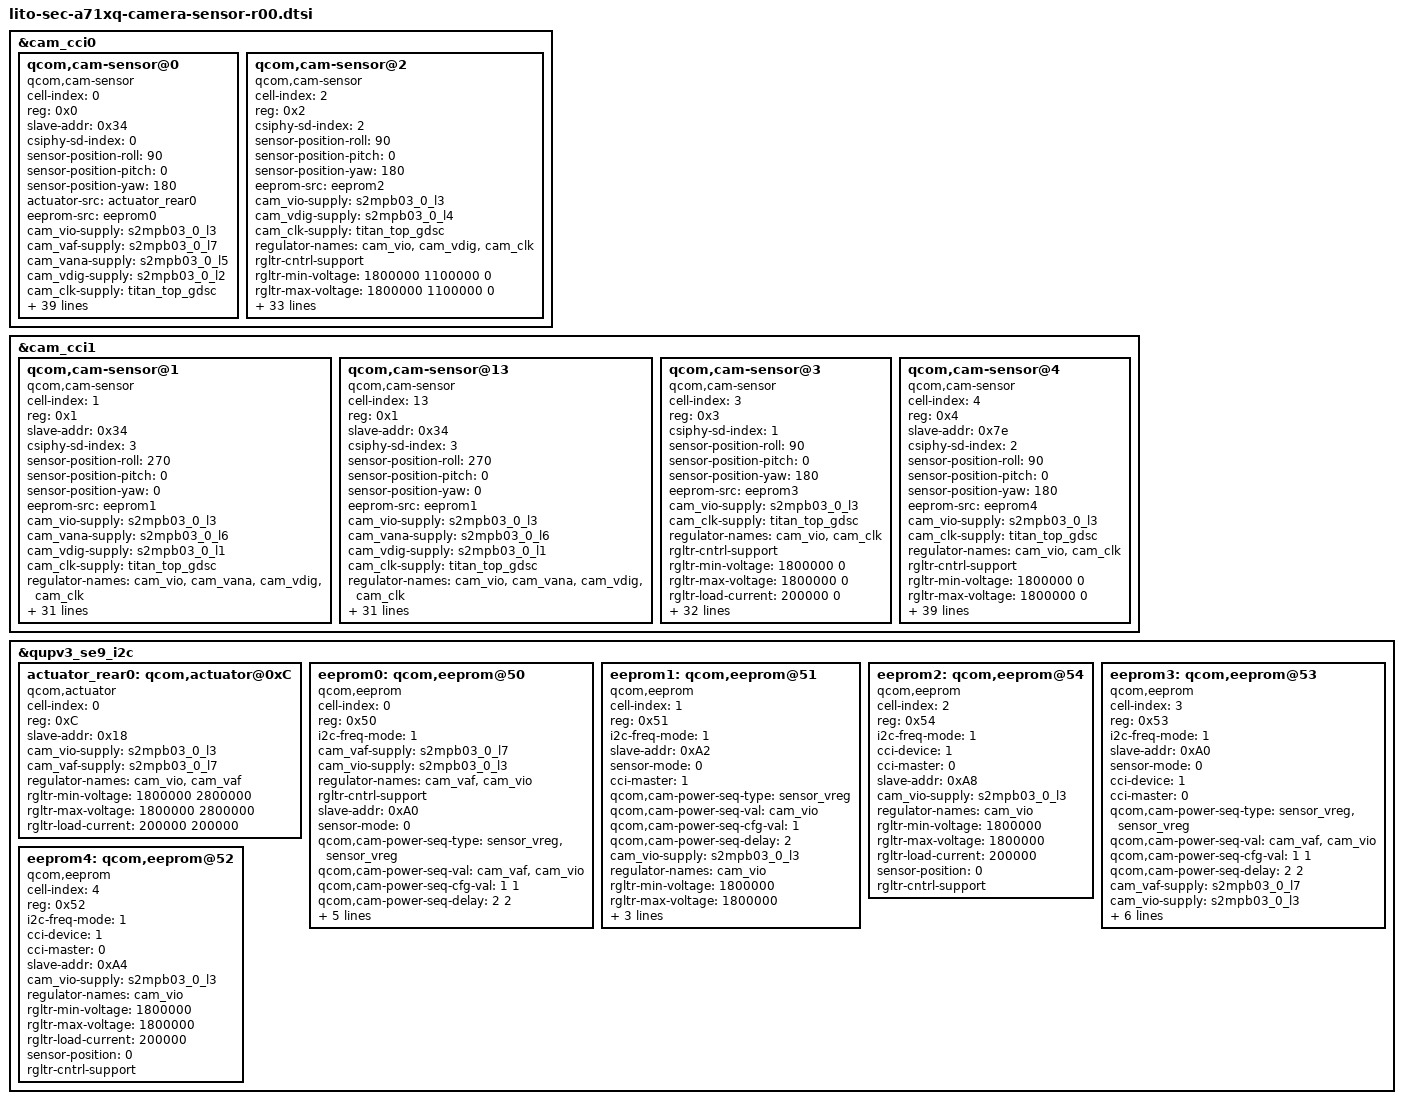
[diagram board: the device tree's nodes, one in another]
/*
 * Copyright (c) 2019, The Linux Foundation. All rights reserved.
 *
 * This program is free software; you can redistribute it and/or modify
 * it under the terms of the GNU General Public License version 2 and
 * only version 2 as published by the Free Software Foundation.
 *
 * This program is distributed in the hope that it will be useful,
 * but WITHOUT ANY WARRANTY; without even the implied warranty of
 * MERCHANTABILITY or FITNESS FOR A PARTICULAR PURPOSE.  See the
 * GNU General Public License for more details.
 */
#include <dt-bindings/clock/qcom,camcc-lito.h>

&cam_cci0 {
	qcom,cam-sensor@0 {
		cell-index = <0>;
		compatible = "qcom,cam-sensor";
		reg = <0x0>;
                slave-addr = <0x34>;
		csiphy-sd-index = <0>;
		sensor-position-roll = <90>;
		sensor-position-pitch = <0>;
		sensor-position-yaw = <180>;

		actuator-src = <&actuator_rear0>;
		//led-flash-src = <&led_flash0>;
		eeprom-src = <&eeprom0>;

		// LDO
		cam_vio-supply = <&s2mpb03_0_l3>;
		cam_vaf-supply = <&s2mpb03_0_l7>;
		cam_vana-supply = <&s2mpb03_0_l5>;
		cam_vdig-supply = <&s2mpb03_0_l2>;
		cam_clk-supply = <&titan_top_gdsc>;
		regulator-names = "cam_vio","cam_vaf", "cam_vana", "cam_vdig", "cam_clk";
		rgltr-cntrl-support;
		rgltr-min-voltage = <1800000 2800000 2900000 1100000 0>;
		rgltr-max-voltage = <1800000 2800000 2900000 1100000 0>;
		rgltr-load-current = <200000 200000 200000 200000 0>;

		// GPIO
		gpio-no-mux = <0>;
		pinctrl-names = "cam_default", "cam_suspend";
		pinctrl-0 = <&cam_sensor_mclk0_active &cam_sensor_rear_active &rcam0_avdd_1p8_active>;
		pinctrl-1 = <&cam_sensor_mclk0_suspend &cam_sensor_rear_suspend &rcam0_avdd_1p8_suspend>;

		gpios = <&tlmm 13 0>,  // MCLK 
			<&tlmm 30 0>,     // RST 
			<&tlmm 22 0>;
		gpio-reset = <1>;
		gpio-req-tbl-num = <0 1 2>;
		gpio-req-tbl-flags = <1 0 0>;
		gpio-req-tbl-label = "CAMIF_MCLK0", "CAM_RESET0", "RCAM0_AV1P8";


		sensor-mode = <0>;
		cci-device = <0>;
		cci-master = <0>;
		status = "ok";
		clocks = <&camcc CAM_CC_MCLK0_CLK>;
		clock-names = "cam_clk";
		clock-cntl-level = "turbo";
		clock-rates = <19200000>;

		cam,isp = <0>;                  // 0 : INT , 1 : EXT , 2 : SOC
		cam,cal_memory = <2>;           // 0 : N , 1 : FROM , 2 : EEPROM , 3 : OTP
		cam,read_version = <1>;         // 0 : SYSFS , 1 : CAMON
		cam,core_voltage = <1>;         // 0 : N , 1 : Y
		cam,upgrade = <2>;              // 0 : N , 1 : SYSFS , 2 : CAMON
		cam,fw_write = <3>;             // 0 : N , 1 : OS , 2 : SD , 3 : ALL
		cam,fw_dump = <1>;              // 0 : N , 1 : Y
		cam,companion_chip = <0>;       // 0 : N , 1 : Y
		cam,ois = <0>;                  // 0 : N , 1 : Y
		cam,dual_open = <0>;            // 0 : N , 1 : Y
		cam,valid = <1>;                // 0 : N , 1 : Y
	};

	qcom,cam-sensor@2 { // REAR CAM 2 - 13MP UW 
		cell-index = <2>;
		compatible = "qcom,cam-sensor";
		reg = <0x2>;
		csiphy-sd-index = <2>;
		sensor-position-roll = <90>;
		sensor-position-pitch = <0>;
		sensor-position-yaw = <180>;
		eeprom-src = <&eeprom2>;
		
		cam_vio-supply = <&s2mpb03_0_l3>;
		cam_vdig-supply = <&s2mpb03_0_l4>; 
		cam_clk-supply = <&titan_top_gdsc>;
		regulator-names =  "cam_vio", "cam_vdig", "cam_clk";
		rgltr-cntrl-support;
		rgltr-min-voltage = <1800000 1100000 0>;
		rgltr-max-voltage = <1800000 1100000 0>;
		rgltr-load-current = <200000 200000 0>;

		gpio-no-mux = <0>;
		pinctrl-names = "cam_default", "cam_suspend";
		pinctrl-0 = <&cam_sensor_mclk3_active &cam_sensor_rear3sw_active &cam_rear3_pwr_active &cam_mipi_sel_active>;
		pinctrl-1 = <&cam_sensor_mclk3_suspend &cam_sensor_rear3sw_suspend &cam_rear3_pwr_suspend &cam_mipi_sel_suspend>;
		gpios = <&tlmm 15 0>, // MCLK 
		       	<&tlmm 21 0>, // RESET 
		        <&tlmm 4 0>, // VANA
		        <&tlmm 66 0>; //MIPI SEL	    



		gpio-reset = <1>;
		gpio-vana = <2>;
		gpio-custom1 = <3>;
		gpio-req-tbl-num = <0 1 2 3>;
		gpio-req-tbl-flags = <1 0 0 0>;
		gpio-req-tbl-label = "CAMIF_MCLK2", "CAM_RESET3", "CAM_VANA", "MIPI_SEL";
		
		sensor-mode = <0>;
		cci-device = <0>;
		cci-master = <1>;
		status = "ok";
		clocks = <&camcc CAM_CC_MCLK2_CLK>;
		clock-names = "cam_clk";
		clock-cntl-level = "turbo";
		clock-rates = <24000000>;

		cam,isp = <0>;                  // 0 : INT , 1 : EXT , 2 : SOC
		cam,cal_memory = <2>;           // 0 : N , 1 : FROM , 2 : EEPROM , 3 : OTP
		cam,read_version = <1>;         // 0 : SYSFS , 1 : CAMON
		cam,core_voltage = <1>;         // 0 : N , 1 : Y
		cam,upgrade = <2>;              // 0 : N , 1 : SYSFS , 2 : CAMON
		cam,fw_write = <3>;             // 0 : N , 1 : OS , 2 : SD , 3 : ALL
		cam,fw_dump = <1>;              // 0 : N , 1 : Y
		cam,companion_chip = <0>;       // 0 : N , 1 : Y
		cam,ois = <0>;                  // 0 : N , 1 : Y
		cam,dual_open = <0>;            // 0 : N , 1 : Y
		cam,valid = <1>;                // 0 : N , 1 : Y
	};
};

&cam_cci1 {
	qcom,cam-sensor@1 {   // VT 32M 
		cell-index = <1>;
		compatible = "qcom,cam-sensor";
		reg = <0x1>;
		slave-addr = <0x34>;
		csiphy-sd-index = <3>;
		sensor-position-roll = <270>;
		sensor-position-pitch = <0>;
		sensor-position-yaw = <0>;

		eeprom-src = <&eeprom1>;

		// LDO
		cam_vio-supply = <&s2mpb03_0_l3>;
		cam_vana-supply = <&s2mpb03_0_l6>;
		cam_vdig-supply = <&s2mpb03_0_l1>;
		cam_clk-supply = <&titan_top_gdsc>;
		regulator-names = "cam_vio", "cam_vana", "cam_vdig", "cam_clk";
		rgltr-cntrl-support;
		rgltr-min-voltage = <1800000 2900000 1050000 0>;
		rgltr-max-voltage = <1800000 2900000 1050000 0>;
		rgltr-load-current = <200000 200000 200000 0>;

		// GPIO
		gpio-no-mux = <0>;
		pinctrl-names = "cam_default", "cam_suspend";
		pinctrl-0 = <&cam_sensor_mclk1_active &cam_sensor_front_active>;
		pinctrl-1 = <&cam_sensor_mclk1_suspend &cam_sensor_front_suspend >;

		gpios = <&tlmm 16 0>,  // MCLK
		     <&tlmm 91 0>;   //RST
			
			
		gpio-reset = <1>;
		gpio-req-tbl-num = <0 1>;
		gpio-req-tbl-flags = <1 0>;
		gpio-req-tbl-label = "CAMIF_MCLK2", "CAM_RESET2";

		sensor-mode = <0>;
		cci-device = <1>;
		cci-master = <0>;
		status = "ok";
		clocks = <&camcc CAM_CC_MCLK3_CLK>;
		clock-names = "cam_clk";
		clock-cntl-level = "turbo";
		clock-rates = <24000000>;

		cam,isp = <0>;                  // 0 : INT , 1 : EXT , 2 : SOC
		cam,cal_memory = <2>;           // 0 : N , 1 : FROM , 2 : EEPROM , 3 : OTP
		cam,read_version = <0>;         // 0 : SYSFS , 1 : CAMON
		cam,core_voltage = <0>;         // 0 : N , 1 : Y
		cam,upgrade = <0>;              // 0 : N , 1 : SYSFS , 2 : CAMON
		cam,fw_write = <0>;             // 0 : N , 1 : OS , 2 : SD , 3 : ALL
		cam,fw_dump = <0>;              // 0 : N , 1 : Y
		cam,companion_chip = <0>;       // 0 : N , 1 : Y
		cam,ois = <0>;                  // 0 : N , 1 : Y
		cam,dual_open = <0>;            // 0 : N , 1 : Y
		cam,valid = <1>;
	};
 
       qcom,cam-sensor@13 {   // VT 32M 
		cell-index = <13>;
		compatible = "qcom,cam-sensor";
		reg = <0x1>;
		slave-addr = <0x34>;
		csiphy-sd-index = <3>;
		sensor-position-roll = <270>;
		sensor-position-pitch = <0>;
		sensor-position-yaw = <0>;

		eeprom-src = <&eeprom1>;

		// LDO
		cam_vio-supply = <&s2mpb03_0_l3>;
		cam_vana-supply = <&s2mpb03_0_l6>;
		cam_vdig-supply = <&s2mpb03_0_l1>;
		cam_clk-supply = <&titan_top_gdsc>;
		regulator-names = "cam_vio", "cam_vana", "cam_vdig", "cam_clk";
		rgltr-cntrl-support;
		rgltr-min-voltage = <1800000 2900000 1050000 0>;
		rgltr-max-voltage = <1800000 2900000 1050000 0>;
		rgltr-load-current = <200000 200000 200000 0>;

		// GPIO
		gpio-no-mux = <0>;
		pinctrl-names = "cam_default", "cam_suspend";
		pinctrl-0 = <&cam_sensor_mclk1_active &cam_sensor_front_active>;
		pinctrl-1 = <&cam_sensor_mclk1_suspend &cam_sensor_front_suspend >;

		gpios = <&tlmm 16 0>,  // MCLK
		     <&tlmm 91 0>;   //RST
			
			
		gpio-reset = <1>;
		gpio-req-tbl-num = <0 1>;
		gpio-req-tbl-flags = <1 0>;
		gpio-req-tbl-label = "CAMIF_MCLK2", "CAM_RESET2";

		sensor-mode = <0>;
		cci-device = <1>;
		cci-master = <0>;
		status = "ok";
		clocks = <&camcc CAM_CC_MCLK3_CLK>;
		clock-names = "cam_clk";
		clock-cntl-level = "turbo";
		clock-rates = <24000000>;

		cam,isp = <0>;                  // 0 : INT , 1 : EXT , 2 : SOC
		cam,cal_memory = <2>;           // 0 : N , 1 : FROM , 2 : EEPROM , 3 : OTP
		cam,read_version = <0>;         // 0 : SYSFS , 1 : CAMON
		cam,core_voltage = <0>;         // 0 : N , 1 : Y
		cam,upgrade = <0>;              // 0 : N , 1 : SYSFS , 2 : CAMON
		cam,fw_write = <0>;             // 0 : N , 1 : OS , 2 : SD , 3 : ALL
		cam,fw_dump = <0>;              // 0 : N , 1 : Y
		cam,companion_chip = <0>;       // 0 : N , 1 : Y
		cam,ois = <0>;                  // 0 : N , 1 : Y
		cam,dual_open = <0>;            // 0 : N , 1 : Y
		cam,valid = <1>;
	};

	qcom,cam-sensor@3 {  // REAR CAM 3 - 5M 
		cell-index = <3>;
		compatible = "qcom,cam-sensor";
		reg = <0x3>;
		csiphy-sd-index = <1>;
		sensor-position-roll = <90>;
		sensor-position-pitch = <0>;
		sensor-position-yaw = <180>;
		eeprom-src = <&eeprom3>;


		// LDO
		cam_vio-supply = <&s2mpb03_0_l3>;
		cam_clk-supply = <&titan_top_gdsc>;
		regulator-names = "cam_vio", "cam_clk";
		rgltr-cntrl-support;
		rgltr-min-voltage = <1800000 0>;
		rgltr-max-voltage = <1800000 0>;
		rgltr-load-current = <200000 0>;

		// GPIO
		gpio-no-mux = <0>;
		pinctrl-names = "cam_default", "cam_suspend";
		pinctrl-0 = <&cam_sensor_mclk2_active &cam_sensor_rear_sub2_active &rcam2_avdd_active &rcam2_dvdd_active>;
		pinctrl-1 = <&cam_sensor_mclk2_suspend &cam_sensor_rear_sub2_suspend &rcam2_avdd_suspend &rcam2_dvdd_suspend>;

		gpios = <&tlmm 14 0>,
			<&tlmm 29 0>,
			<&tlmm 24 0>,
			<&tlmm 44 0>;

		gpio-reset = <1>;
		gpio-vana = <2>;
		gpio-vdig = <3>;
		gpio-req-tbl-num = <0 1 2 3>;
		gpio-req-tbl-flags = <1 0 0 0>;
		gpio-req-tbl-label = "CAMIF_MCLK3", "CAM_RESET2", "CAM_VANA", "CAM_VDIG";

		sensor-mode = <0>;
		cci-device = <1>;
		cci-master = <0>;
		status = "ok";
		clocks = <&camcc CAM_CC_MCLK1_CLK>;
		clock-names = "cam_clk";
		clock-cntl-level = "turbo";
		clock-rates = <24000000>;

		cam,isp = <0>;                  // 0 : INT , 1 : EXT , 2 : SOC
		cam,cal_memory = <0>;           // 0 : N , 1 : FROM , 2 : EEPROM , 3 : OTP
		cam,read_version = <0>;         // 0 : SYSFS , 1 : CAMON
		cam,core_voltage = <0>;         // 0 : N , 1 : Y
		cam,upgrade = <0>;              // 0 : N , 1 : SYSFS , 2 : CAMON
		cam,fw_write = <0>;             // 0 : N , 1 : OS , 2 : SD , 3 : ALL
		cam,fw_dump = <0>;              // 0 : N , 1 : Y
		cam,companion_chip = <0>;       // 0 : N , 1 : Y
		cam,ois = <0>;                  // 0 : N , 1 : Y
		cam,dual_open = <0>;            // 0 : N , 1 : Y
		cam,valid = <1>;
	};

	qcom,cam-sensor@4 {   //REAR CAM 4 - 5M Macro  
		cell-index = <4>;
		compatible = "qcom,cam-sensor";
		reg = <0x4>;
                slave-addr = <0x7e>;
		csiphy-sd-index = <2>;
		sensor-position-roll = <90>;
		sensor-position-pitch = <0>;
		sensor-position-yaw = <180>;
  		//led-flash-src = <&led_flash0>;
		eeprom-src = <&eeprom4>;

		// LDO
                cam_vio-supply = <&s2mpb03_0_l3>;
		cam_clk-supply = <&titan_top_gdsc>;
		regulator-names = "cam_vio", "cam_clk";
		rgltr-cntrl-support;
		rgltr-min-voltage = <1800000 0>;
		rgltr-max-voltage = <1800000 0>;
		rgltr-load-current = <200000 0>;


		// GPIO
		gpio-no-mux = <0>;
		pinctrl-names = "cam_default", "cam_suspend";
		pinctrl-0 = <&cam_sensor_mclk4_active &cam_sensor_rear4sw_active &cam_sensor_rear4_pwr_active &cam_sensor_rear4_digital_active &cam_mipi_sel_active>;
		pinctrl-1 = <&cam_sensor_mclk4_suspend &cam_sensor_rear4sw_suspend &cam_sensor_rear4_pwr_suspend &cam_sensor_rear4_digital_suspend &cam_mipi_sel_suspend>;

		gpios = <&tlmm 25 0>,
			<&tlmm 23 0>,
			<&tlmm 63 0>,
			<&tlmm 64 0>,
			<&tlmm 66 0>;

		gpio-reset = <1>;
		gpio-vana = <2>;
		gpio-vdig = <3>;
		gpio-custom1 = <4>;
		gpio-req-tbl-num = <0 1 2 3 4>;
		gpio-req-tbl-flags = <1 0 0 0 0>;
		gpio-req-tbl-label = "CAMIF_MCLK3", "CAM_RESET2", "CAM_VANA", "CAM_VDIG", "MIPI_SEL";

		sensor-mode = <0>;
		cci-device = <1>;
		cci-master = <0>;
		status = "ok";
		clocks = <&camcc CAM_CC_MCLK4_CLK>;
		clock-names = "cam_clk";
		clock-cntl-level = "turbo";
		clock-rates = <24000000>;

		cam,isp = <0>;                  // 0 : INT , 1 : EXT , 2 : SOC
		cam,cal_memory = <0>;           // 0 : N , 1 : FROM , 2 : EEPROM , 3 : OTP
		cam,read_version = <0>;         // 0 : SYSFS , 1 : CAMON
		cam,core_voltage = <0>;         // 0 : N , 1 : Y
		cam,upgrade = <0>;              // 0 : N , 1 : SYSFS , 2 : CAMON
		cam,fw_write = <0>;             // 0 : N , 1 : OS , 2 : SD , 3 : ALL
		cam,fw_dump = <0>;              // 0 : N , 1 : Y
		cam,companion_chip = <0>;       // 0 : N , 1 : Y
		cam,ois = <0>;                  // 0 : N , 1 : Y
		cam,dual_open = <0>;            // 0 : N , 1 : Y
		cam,valid = <1>;                // 0 : N , 1 : Y
	};
};

&qupv3_se9_i2c {
    status = "ok";
    actuator_rear0: qcom,actuator@0xC {
		cell-index = <0>;
		reg = <0xC>;
		slave-addr = <0x18>;
		compatible = "qcom,actuator";
		cam_vio-supply = <&s2mpb03_0_l3>;
		cam_vaf-supply = <&s2mpb03_0_l7>;
		regulator-names = "cam_vio","cam_vaf";
        	rgltr-min-voltage = <1800000 2800000>;
        	rgltr-max-voltage = <1800000 2800000>;
		rgltr-load-current = <200000 200000>;
	};

	eeprom0: qcom,eeprom@50 {
		cell-index = <0>;
		reg = <0x50>;
		compatible = "qcom,eeprom";
		i2c-freq-mode = <1>;
		cam_vaf-supply = <&s2mpb03_0_l7>;
		cam_vio-supply = <&s2mpb03_0_l3>;
		regulator-names = "cam_vaf","cam_vio";
		rgltr-cntrl-support;
		slave-addr = <0xA0>;
		sensor-mode = <0>;
		//cci-device = <1>;
		//cci-master = <0>;

		qcom,cam-power-seq-type = "sensor_vreg", "sensor_vreg";
        qcom,cam-power-seq-val = "cam_vaf", "cam_vio";
        qcom,cam-power-seq-cfg-val = <1 1>;
        qcom,cam-power-seq-delay = <2 2>;

		rgltr-min-voltage = <2800000 1800000>;
		rgltr-max-voltage = <2800000 1800000>;
		rgltr-load-current = <200000 200000>;
		sensor-position = <0>;

		gpio-no-mux = <0>;
	};

	eeprom1: qcom,eeprom@51 {
        cell-index = <1>;
        reg = <0x51>;//QUP use 0xA2, 51
        compatible = "qcom,eeprom";
        i2c-freq-mode = <1>;
        slave-addr = <0xA2>;
        sensor-mode = <0>;
        cci-master = <1>;

        qcom,cam-power-seq-type = "sensor_vreg";
        qcom,cam-power-seq-val = "cam_vio";
        qcom,cam-power-seq-cfg-val = <1>;
        qcom,cam-power-seq-delay = <2>;

        cam_vio-supply = <&s2mpb03_0_l3>;
        regulator-names = "cam_vio";
        rgltr-min-voltage = <1800000>;
        rgltr-max-voltage = <1800000>;
        rgltr-load-current = <200000>;

        sensor-position = <1>;
        rgltr-cntrl-support;
	};

    eeprom2: qcom,eeprom@54 {
        cell-index = <2>;
        reg = <0x54>;
        compatible = "qcom,eeprom";
        i2c-freq-mode = <1>;
        cci-device = <1>;
        cci-master = <0>;
        slave-addr = <0xA8>;

        cam_vio-supply = <&s2mpb03_0_l3>;

        regulator-names = "cam_vio";
        rgltr-min-voltage = <1800000>;
        rgltr-max-voltage = <1800000>;
        rgltr-load-current = <200000>;
        sensor-position = <0>;
        rgltr-cntrl-support;
	};

    eeprom3: qcom,eeprom@53 {
        cell-index = <3>;
        reg = <0x53>;
        compatible = "qcom,eeprom";
        i2c-freq-mode = <1>;
        slave-addr = <0xA0>;
        sensor-mode = <0>;
        cci-device = <1>;
        cci-master = <0>;

        qcom,cam-power-seq-type = "sensor_vreg", "sensor_vreg";
        qcom,cam-power-seq-val = "cam_vaf", "cam_vio";
        qcom,cam-power-seq-cfg-val = <1 1>;
        qcom,cam-power-seq-delay = <2 2>;

        cam_vaf-supply = <&s2mpb03_0_l7>;
        cam_vio-supply = <&s2mpb03_0_l3>;

        regulator-names = "cam_vaf","cam_vio";
        rgltr-min-voltage = <2800000 1800000>;
        rgltr-max-voltage = <2800000 1800000>;
        rgltr-load-current = <200000 200000>;
        sensor-position = <0>;
        rgltr-cntrl-support;
    };

    eeprom4: qcom,eeprom@52 {
        cell-index = <4>;
        reg = <0x52>;
        compatible = "qcom,eeprom";
        i2c-freq-mode = <1>;
        cci-device = <1>;
        cci-master = <0>;
        slave-addr = <0xA4>;

        cam_vio-supply = <&s2mpb03_0_l3>;

        regulator-names = "cam_vio";
        rgltr-min-voltage = <1800000>;
        rgltr-max-voltage = <1800000>;
        rgltr-load-current = <200000>;
        sensor-position = <0>;
        rgltr-cntrl-support;
    };
};




